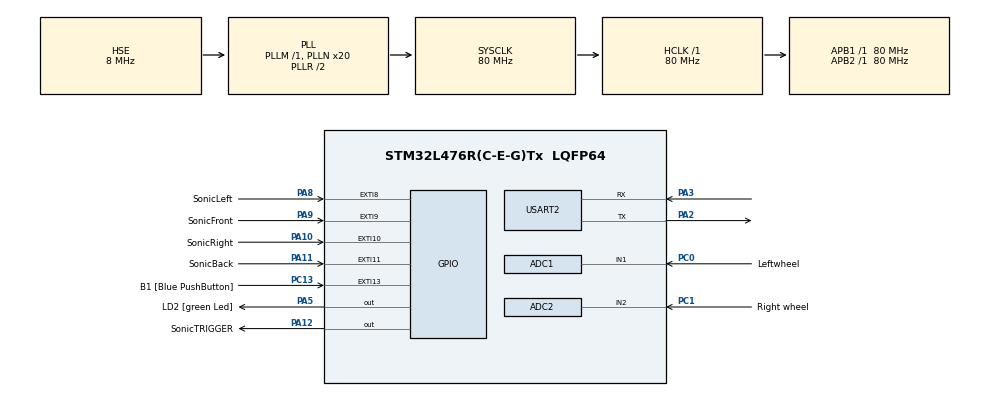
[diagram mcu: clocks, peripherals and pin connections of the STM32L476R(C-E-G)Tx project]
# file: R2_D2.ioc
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ADC1.Channel-0\#ChannelRegularConversion=ADC_CHANNEL_1
ADC1.EnableAnalogWatchDog1=false
ADC1.NbrOfConversionFlag=1
ADC1.OffsetNumber-0\#ChannelRegularConversion=ADC_OFFSET_NONE
ADC1.Rank-0\#ChannelRegularConversion=1
ADC1.SamplingTime-0\#ChannelRegularConversion=ADC_SAMPLETIME_2CYCLES_5
ADC1.master=1
ADC2.Channel-0\#ChannelRegularConversion=ADC_CHANNEL_2
ADC2.NbrOfConversionFlag=1
ADC2.OffsetNumber-0\#ChannelRegularConversion=ADC_OFFSET_NONE
ADC2.Rank-0\#ChannelRegularConversion=1
ADC2.SamplingTime-0\#ChannelRegularConversion=ADC_SAMPLETIME_2CYCLES_5
FREERTOS.INCLUDE_vTaskDelayUntil=1
FREERTOS.Tasks01=defaultTask,0,128,StartDefaultTask,Default,NULL
FREERTOS.configTOTAL_HEAP_SIZE=12000
FREERTOS.configUSE_COUNTING_SEMAPHORES=1
FREERTOS.configUSE_RECURSIVE_MUTEXES=1
FREERTOS.configUSE_TICKLESS_IDLE=1
FREERTOS.configUSE_TIMERS=1
IWDG.Prescaler=IWDG_PRESCALER_16
Mcu.Family=STM32L4
Mcu.Name=STM32L476R(C-E-G)Tx
Mcu.Package=LQFP64
NVIC.ADC1_2_IRQn=true\:0\:0\:false\:false\:true\:false
NVIC.EXTI15_10_IRQn=true\:5\:0\:false\:true\:true\:2\:true
NVIC.EXTI9_5_IRQn=true\:5\:0\:false\:true\:true\:1\:true
NVIC.PriorityGroup=NVIC_PRIORITYGROUP_4
NVIC.TIM1_UP_TIM16_IRQn=true\:0\:0\:false\:false\:true\:false
NVIC.TIM6_DAC_IRQn=true\:0\:0\:false\:false\:true\:false
NVIC.TimeBase=TIM1_UP_TIM16_IRQn
NVIC.TimeBaseIP=TIM1
PA10.GPIO_Label=SonicRight
PA10.GPIO_ModeDefaultEXTI=GPIO_MODE_IT_RISING_FALLING
PA10.Signal=GPXTI10
PA11.GPIO_Label=SonicBack
PA11.GPIO_ModeDefaultEXTI=GPIO_MODE_IT_RISING_FALLING
PA11.Signal=GPXTI11
PA12.GPIO_Label=SonicTRIGGER
PA12.GPIO_ModeDefaultOutputPP=GPIO_MODE_OUTPUT_PP
PA12.GPIO_PuPd=GPIO_NOPULL
PA12.GPIO_Speed=GPIO_SPEED_FREQ_VERY_HIGH
PA12.PinState=GPIO_PIN_RESET
PA12.Signal=GPIO_Output
PA13\ (JTMS-SWDIO).GPIO_Label=TMS
PA13\ (JTMS-SWDIO).Signal=SYS_JTMS-SWDIO
PA14\ (JTCK-SWCLK).GPIO_Label=TCK
PA14\ (JTCK-SWCLK).Signal=SYS_JTCK-SWCLK
PA2.Mode=Asynchronous
PA2.Signal=USART2_TX
PA3.Mode=Asynchronous
PA3.Signal=USART2_RX
PA5.GPIO_Label=LD2 [green Led]
PA5.GPIO_ModeDefaultOutputPP=GPIO_MODE_OUTPUT_PP
PA5.GPIO_PuPd=GPIO_NOPULL
PA5.GPIO_Speed=GPIO_SPEED_FREQ_LOW
PA5.Signal=GPIO_Output
PA8.GPIO_Label=SonicLeft
PA8.GPIO_ModeDefaultEXTI=GPIO_MODE_IT_RISING_FALLING
PA8.Signal=GPXTI8
PA9.GPIO_Label=SonicFront
PA9.GPIO_ModeDefaultEXTI=GPIO_MODE_IT_RISING_FALLING
PA9.Signal=GPXTI9
PB3\ (JTDO-TRACESWO).GPIO_Label=SWO
PB3\ (JTDO-TRACESWO).Signal=SYS_JTDO-SWO
PC0.GPIO_Label=Leftwheel
PC0.GPIO_Mode=GPIO_MODE_ANALOG_ADC_CONTROL
PC0.GPIO_PuPd=GPIO_NOPULL
PC0.Signal=ADCx_IN1
PC1.GPIO_Label=Right wheel
PC1.Signal=ADCx_IN2
PC13.GPIO_Label=B1 [Blue PushButton]
PC13.GPIO_ModeDefaultEXTI=GPIO_MODE_IT_FALLING
PC13.GPIO_PuPd=GPIO_NOPULL
PC13.Signal=GPXTI13
PC14-OSC32_IN\ (PC14).Mode=LSE-External-Oscillator
PC14-OSC32_IN\ (PC14).Signal=RCC_OSC32_IN
PC15-OSC32_OUT\ (PC15).Mode=LSE-External-Oscillator
PC15-OSC32_OUT\ (PC15).Signal=RCC_OSC32_OUT
PH0-OSC_IN\ (PH0).Mode=HSE-External-Oscillator
PH0-OSC_IN\ (PH0).Signal=RCC_OSC_IN
PH1-OSC_OUT\ (PH1).Mode=HSE-External-Oscillator
PH1-OSC_OUT\ (PH1).Signal=RCC_OSC_OUT
ProjectManager.HeapSize=0x200
ProjectManager.StackSize=0x400
ProjectManager.TargetToolchain=SW4STM32
RCC.ADCCLockSelection=RCC_ADCCLKSOURCE_SYSCLK
RCC.ADCFreq_Value=80000000
RCC.AHBFreq_Value=80000000
RCC.APB1Freq_Value=80000000
RCC.APB1TimFreq_Value=80000000
RCC.APB2Freq_Value=80000000
RCC.APB2TimFreq_Value=80000000
RCC.CortexFreq_Value=80000000
RCC.EnbaleCSS=true
RCC.HCLKFreq_Value=80000000
RCC.HSE_VALUE=8000000
RCC.HSI_VALUE=16000000
RCC.MSI_VALUE=4000000
RCC.PLLN=20
RCC.PLLSourceVirtual=RCC_PLLSOURCE_HSE
RCC.PREFETCH_ENABLE=1
RCC.SYSCLKFreq_VALUE=80000000
RCC.SYSCLKSource=RCC_SYSCLKSOURCE_PLLCLK
RCC.USART2CLockSelection=RCC_USART2CLKSOURCE_SYSCLK
RCC.USBFreq_Value=32000000
RCC.VCOOutputFreq_Value=160000000
SH.ADCx_IN1.0=ADC1_IN1,IN1-Single-Ended
SH.ADCx_IN2.0=ADC2_IN2,IN2-Single-Ended
TIM6.Period=65535
USART2.VirtualMode-Asynchronous=VM_ASYNC
VP_FREERTOS_VS_ENABLE.Mode=Enabled
VP_IWDG_VS_IWDG.Mode=IWDG_Activate
VP_SYS_VS_tim1.Mode=TIM1
VP_TIM6_VS_ClockSourceINT.Mode=Enable_Timer
VP_WWDG_VS_WWDG.Mode=WWDG_Activate
board=NUCLEO-L476RG

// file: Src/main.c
/**
  ******************************************************************************
  * File Name          : main.c
  * Description        : Main program body
  ******************************************************************************
  * This notice applies to any and all portions of this file
  * that are not between comment pairs USER CODE BEGIN and
  * USER CODE END. Other portions of this file, whether
  * inserted by the user or by software development tools
  * are owned by their respective copyright owners.
  *
  * Copyright (c) 2017 STMicroelectronics International N.V.
  * All rights reserved.
  *
  * Redistribution and use in source and binary forms, with or without
  * modification, are permitted, provided that the following conditions are met:
  *
  * 1. Redistribution of source code must retain the above copyright notice,
  *    this list of conditions and the following disclaimer.
  * 2. Redistributions in binary form must reproduce the above copyright notice,
  *    this list of conditions and the following disclaimer in the documentation
  *    and/or other materials provided with the distribution.
  * 3. Neither the name of STMicroelectronics nor the names of other
  *    contributors to this software may be used to endorse or promote products
  *    derived from this software without specific written permission.
  * 4. This software, including modifications and/or derivative works of this
  *    software, must execute solely and exclusively on microcontroller or
  *    microprocessor devices manufactured by or for STMicroelectronics.
  * 5. Redistribution and use of this software other than as permitted under
  *    this license is void and will automatically terminate your rights under
  *    this license.
  *
  * THIS SOFTWARE IS PROVIDED BY STMICROELECTRONICS AND CONTRIBUTORS "AS IS"
  * AND ANY EXPRESS, IMPLIED OR STATUTORY WARRANTIES, INCLUDING, BUT NOT
  * LIMITED TO, THE IMPLIED WARRANTIES OF MERCHANTABILITY, FITNESS FOR A
  * PARTICULAR PURPOSE AND NON-INFRINGEMENT OF THIRD PARTY INTELLECTUAL PROPERTY
  * RIGHTS ARE DISCLAIMED TO THE FULLEST EXTENT PERMITTED BY LAW. IN NO EVENT
  * SHALL STMICROELECTRONICS OR CONTRIBUTORS BE LIABLE FOR ANY DIRECT, INDIRECT,
  * INCIDENTAL, SPECIAL, EXEMPLARY, OR CONSEQUENTIAL DAMAGES (INCLUDING, BUT NOT
  * LIMITED TO, PROCUREMENT OF SUBSTITUTE GOODS OR SERVICES; LOSS OF USE, DATA,
  * OR PROFITS; OR BUSINESS INTERRUPTION) HOWEVER CAUSED AND ON ANY THEORY OF
  * LIABILITY, WHETHER IN CONTRACT, STRICT LIABILITY, OR TORT (INCLUDING
  * NEGLIGENCE OR OTHERWISE) ARISING IN ANY WAY OUT OF THE USE OF THIS SOFTWARE,
  * EVEN IF ADVISED OF THE POSSIBILITY OF SUCH DAMAGE.
  *
  ******************************************************************************
  */
#include "main.h"
#include "stm32l4xx_hal.h"
#include "cmsis_os.h"
#include "adc.h"
#include "iwdg.h"
#include "tim.h"
#include "usart.h"
#include "wwdg.h"
#include "gpio.h"

/* USER CODE BEGIN PV */
/* Private variables ---------------------------------------------------------*/

/* USER CODE END PV */

void SystemClock_Config(void);
void MX_FREERTOS_Init(void);
static void MX_NVIC_Init(void);

/* USER CODE BEGIN PFP */
/* Private function prototypes -----------------------------------------------*/

/* USER CODE END PFP */

int main(void)
{

  /* MCU Configuration----------------------------------------------------------*/

  /* Reset of all peripherals, Initializes the Flash interface and the Systick. */
  HAL_Init();

  /* Configure the system clock */
  SystemClock_Config();

  /* Initialize all configured peripherals */
  MX_GPIO_Init();
  MX_IWDG_Init();
  MX_TIM6_Init();
  MX_WWDG_Init();
  MX_ADC1_Init();
  MX_ADC2_Init();
  MX_USART2_UART_Init();

  /* Initialize interrupts */
  MX_NVIC_Init();

  /* Call init function for freertos objects (in freertos.c) */
  MX_FREERTOS_Init();

  /* Start scheduler */
  osKernelStart();

  /* We should never get here as control is now taken by the scheduler */

  /* Infinite loop */
  while (1)
  {

  }

}

/** System Clock Configuration
*/
void SystemClock_Config(void)
{

  RCC_OscInitTypeDef RCC_OscInitStruct;
  RCC_ClkInitTypeDef RCC_ClkInitStruct;
  RCC_PeriphCLKInitTypeDef PeriphClkInit;

    /**Initializes the CPU, AHB and APB busses clocks
    */
  RCC_OscInitStruct.OscillatorType = RCC_OSCILLATORTYPE_LSI|RCC_OSCILLATORTYPE_HSE;
  RCC_OscInitStruct.HSEState = RCC_HSE_ON;
  RCC_OscInitStruct.LSIState = RCC_LSI_ON;
  RCC_OscInitStruct.PLL.PLLState = RCC_PLL_ON;
  RCC_OscInitStruct.PLL.PLLSource = RCC_PLLSOURCE_HSE;
  RCC_OscInitStruct.PLL.PLLM = 1;
  RCC_OscInitStruct.PLL.PLLN = 20;
  RCC_OscInitStruct.PLL.PLLP = RCC_PLLP_DIV7;
  RCC_OscInitStruct.PLL.PLLQ = RCC_PLLQ_DIV2;
  RCC_OscInitStruct.PLL.PLLR = RCC_PLLR_DIV2;
  if (HAL_RCC_OscConfig(&RCC_OscInitStruct) != HAL_OK)
  {
    _Error_Handler(__FILE__, __LINE__);
  }

    /**Initializes the CPU, AHB and APB busses clocks
    */
  RCC_ClkInitStruct.ClockType = RCC_CLOCKTYPE_HCLK|RCC_CLOCKTYPE_SYSCLK
                              |RCC_CLOCKTYPE_PCLK1|RCC_CLOCKTYPE_PCLK2;
  RCC_ClkInitStruct.SYSCLKSource = RCC_SYSCLKSOURCE_PLLCLK;
  RCC_ClkInitStruct.AHBCLKDivider = RCC_SYSCLK_DIV1;
  RCC_ClkInitStruct.APB1CLKDivider = RCC_HCLK_DIV1;
  RCC_ClkInitStruct.APB2CLKDivider = RCC_HCLK_DIV1;

  if (HAL_RCC_ClockConfig(&RCC_ClkInitStruct, FLASH_LATENCY_4) != HAL_OK)
  {
    _Error_Handler(__FILE__, __LINE__);
  }

  PeriphClkInit.PeriphClockSelection = RCC_PERIPHCLK_USART2|RCC_PERIPHCLK_ADC;
  PeriphClkInit.Usart2ClockSelection = RCC_USART2CLKSOURCE_SYSCLK;
  PeriphClkInit.AdcClockSelection = RCC_ADCCLKSOURCE_SYSCLK;
  if (HAL_RCCEx_PeriphCLKConfig(&PeriphClkInit) != HAL_OK)
  {
    _Error_Handler(__FILE__, __LINE__);
  }

    /**Enables the Clock Security System
    */
  HAL_RCC_EnableCSS();

    /**Configure the main internal regulator output voltage
    */
  if (HAL_PWREx_ControlVoltageScaling(PWR_REGULATOR_VOLTAGE_SCALE1) != HAL_OK)
  {
    _Error_Handler(__FILE__, __LINE__);
  }

    /**Configure the Systick interrupt time
    */
  HAL_SYSTICK_Config(HAL_RCC_GetHCLKFreq()/1000);

    /**Configure the Systick
    */
  HAL_SYSTICK_CLKSourceConfig(SYSTICK_CLKSOURCE_HCLK);

  /* SysTick_IRQn interrupt configuration */
  HAL_NVIC_SetPriority(SysTick_IRQn, 15, 0);
}

/** NVIC Configuration
*/
static void MX_NVIC_Init(void)
{
  /* EXTI9_5_IRQn interrupt configuration */
  HAL_NVIC_SetPriority(EXTI9_5_IRQn, 5, 0);
  HAL_NVIC_EnableIRQ(EXTI9_5_IRQn);
  /* EXTI15_10_IRQn interrupt configuration */
  HAL_NVIC_SetPriority(EXTI15_10_IRQn, 5, 0);
  HAL_NVIC_EnableIRQ(EXTI15_10_IRQn);
}

void HAL_TIM_PeriodElapsedCallback(TIM_HandleTypeDef *htim)
{
  if (htim->Instance == TIM1) {
    HAL_IncTick();
  }
}

void _Error_Handler(char * file, int line)
{
  while(1)
  {
  }
}

/************************ (C) COPYRIGHT STMicroelectronics *****END OF FILE****/

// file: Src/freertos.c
/**
  ******************************************************************************
  * File Name          : freertos.c
  * Description        : Code for freertos applications
  ******************************************************************************
  * This notice applies to any and all portions of this file
  * that are not between comment pairs USER CODE BEGIN and
  * USER CODE END. Other portions of this file, whether
  * inserted by the user or by software development tools
  * are owned by their respective copyright owners.
  *
  * Copyright (c) 2017 STMicroelectronics International N.V.
  * All rights reserved.
  *
  * Redistribution and use in source and binary forms, with or without
  * modification, are permitted, provided that the following conditions are met:
  *
  * 1. Redistribution of source code must retain the above copyright notice,
  *    this list of conditions and the following disclaimer.
  * 2. Redistributions in binary form must reproduce the above copyright notice,
  *    this list of conditions and the following disclaimer in the documentation
  *    and/or other materials provided with the distribution.
  * 3. Neither the name of STMicroelectronics nor the names of other
  *    contributors to this software may be used to endorse or promote products
  *    derived from this software without specific written permission.
  * 4. This software, including modifications and/or derivative works of this
  *    software, must execute solely and exclusively on microcontroller or
  *    microprocessor devices manufactured by or for STMicroelectronics.
  * 5. Redistribution and use of this software other than as permitted under
  *    this license is void and will automatically terminate your rights under
  *    this license.
  *
  * THIS SOFTWARE IS PROVIDED BY STMICROELECTRONICS AND CONTRIBUTORS "AS IS"
  * AND ANY EXPRESS, IMPLIED OR STATUTORY WARRANTIES, INCLUDING, BUT NOT
  * LIMITED TO, THE IMPLIED WARRANTIES OF MERCHANTABILITY, FITNESS FOR A
  * PARTICULAR PURPOSE AND NON-INFRINGEMENT OF THIRD PARTY INTELLECTUAL PROPERTY
  * RIGHTS ARE DISCLAIMED TO THE FULLEST EXTENT PERMITTED BY LAW. IN NO EVENT
  * SHALL STMICROELECTRONICS OR CONTRIBUTORS BE LIABLE FOR ANY DIRECT, INDIRECT,
  * INCIDENTAL, SPECIAL, EXEMPLARY, OR CONSEQUENTIAL DAMAGES (INCLUDING, BUT NOT
  * LIMITED TO, PROCUREMENT OF SUBSTITUTE GOODS OR SERVICES; LOSS OF USE, DATA,
  * OR PROFITS; OR BUSINESS INTERRUPTION) HOWEVER CAUSED AND ON ANY THEORY OF
  * LIABILITY, WHETHER IN CONTRACT, STRICT LIABILITY, OR TORT (INCLUDING
  * NEGLIGENCE OR OTHERWISE) ARISING IN ANY WAY OUT OF THE USE OF THIS SOFTWARE,
  * EVEN IF ADVISED OF THE POSSIBILITY OF SUCH DAMAGE.
  *
  ******************************************************************************
  */

#include "FreeRTOS.h"
#include "task.h"
#include "cmsis_os.h"

osThreadId defaultTaskHandle;

void StartDefaultTask(void const * argument);

void MX_FREERTOS_Init(void); /* (MISRA C 2004 rule 8.1) */

/* Pre/Post sleep processing prototypes */
void PreSleepProcessing(uint32_t *ulExpectedIdleTime);
void PostSleepProcessing(uint32_t *ulExpectedIdleTime);

/* Hook prototypes */

/* USER CODE BEGIN PREPOSTSLEEP */
__weak void PreSleepProcessing(uint32_t *ulExpectedIdleTime)
{
/* place for user code */
}

__weak void PostSleepProcessing(uint32_t *ulExpectedIdleTime)
{
/* place for user code */
}
/* USER CODE END PREPOSTSLEEP */

/* Init FreeRTOS */

void MX_FREERTOS_Init(void) {

  /* Create the thread(s) */
  /* definition and creation of defaultTask */
  osThreadDef(defaultTask, StartDefaultTask, osPriorityNormal, 0, 128);
  defaultTaskHandle = osThreadCreate(osThread(defaultTask), NULL);

}

/* StartDefaultTask function */
void StartDefaultTask(void const * argument)
{

  for(;;)
  {
    osDelay(1);
  }
}

/************************ (C) COPYRIGHT STMicroelectronics *****END OF FILE****/
